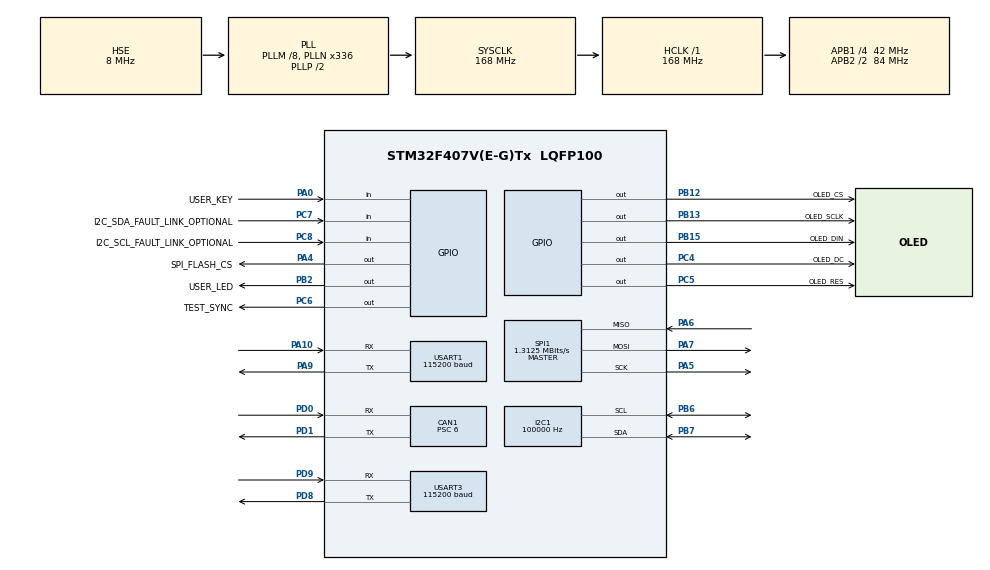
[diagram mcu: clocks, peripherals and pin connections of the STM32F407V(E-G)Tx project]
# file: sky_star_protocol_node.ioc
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CAN1.BS1=CAN_BS1_11TQ
CAN1.BS2=CAN_BS2_2TQ
CAN1.AutoBusOff=ENABLE
CAN1.AutoRetransmission=ENABLE
CAN1.CalculateBaudRate=500000
CAN1.CalculateTimeBit=2000
CAN1.CalculateTimeQuantum=142.85714285714286
CAN1.Prescaler=6
I2C1.ClockSpeed=100000
Mcu.Family=STM32F4
Mcu.Name=STM32F407V(E-G)Tx
Mcu.Package=LQFP100
PB12.GPIO_Label=OLED_CS
PB12.PinState=GPIO_PIN_SET
PB12.Signal=GPIO_Output
PB13.GPIO_Label=OLED_SCLK
PB13.Signal=GPIO_Output
PB15.GPIO_Label=OLED_DIN
PB15.Signal=GPIO_Output
PC4.GPIO_Label=OLED_DC
PC4.Signal=GPIO_Output
PC5.GPIO_Label=OLED_RES
PC5.PinState=GPIO_PIN_SET
PC5.Signal=GPIO_Output
PC7.GPIO_Label=I2C_SDA_FAULT_LINK_OPTIONAL
PC7.Signal=GPIO_Input
PC8.GPIO_Label=I2C_SCL_FAULT_LINK_OPTIONAL
PC8.Signal=GPIO_Input
NVIC.PriorityGroup=NVIC_PRIORITYGROUP_4
NVIC.USART1_IRQn=true\:5\:0\:false\:false\:true\:true\:true\:true
PA0-WKUP.GPIO_Label=USER_KEY
PA0-WKUP.GPIO_PuPd=GPIO_PULLDOWN
PA0-WKUP.Signal=GPIO_Input
PA10.Mode=Asynchronous
PA10.Signal=USART1_RX
PA13.Mode=Serial_Wire
PA13.Signal=SYS_JTMS-SWDIO
PA14.Mode=Serial_Wire
PA14.Signal=SYS_JTCK-SWCLK
PA4.GPIO_Label=SPI_FLASH_CS
PA4.GPIO_Speed=GPIO_SPEED_FREQ_HIGH
PA4.PinState=GPIO_PIN_SET
PA4.Signal=GPIO_Output
PA5.Mode=Full_Duplex_Master
PA5.Signal=SPI1_SCK
PA6.Mode=Full_Duplex_Master
PA6.Signal=SPI1_MISO
PA7.Mode=Full_Duplex_Master
PA7.Signal=SPI1_MOSI
PA9.Mode=Asynchronous
PA9.Signal=USART1_TX
PB2.GPIO_Label=USER_LED
PB2.GPIO_Speed=GPIO_SPEED_FREQ_LOW
PB2.PinState=GPIO_PIN_RESET
PB2.Signal=GPIO_Output
PB6.GPIO_Pu=GPIO_PULLUP
PB6.Mode=I2C
PB6.Signal=I2C1_SCL
PB7.GPIO_Pu=GPIO_PULLUP
PB7.Mode=I2C
PB7.Signal=I2C1_SDA
PC14-OSC32_IN.Mode=LSE-External-Oscillator
PC14-OSC32_IN.Signal=RCC_OSC32_IN
PC15-OSC32_OUT.Mode=LSE-External-Oscillator
PC15-OSC32_OUT.Signal=RCC_OSC32_OUT
PC6.GPIO_Label=TEST_SYNC
PC6.GPIO_Speed=GPIO_SPEED_FREQ_HIGH
PC6.PinState=GPIO_PIN_RESET
PC6.Signal=GPIO_Output
PD0.Mode=CAN_Activate
PD0.Signal=CAN1_RX
PD1.Mode=CAN_Activate
PD1.Signal=CAN1_TX
PD8.Mode=Asynchronous
PD8.Signal=USART3_TX
PD9.Mode=Asynchronous
PD9.Signal=USART3_RX
PH0-OSC_IN.Mode=HSE-External-Oscillator
PH0-OSC_IN.Signal=RCC_OSC_IN
PH1-OSC_OUT.Mode=HSE-External-Oscillator
PH1-OSC_OUT.Signal=RCC_OSC_OUT
ProjectManager.HeapSize=0x400
ProjectManager.StackSize=0x800
ProjectManager.TargetToolchain=MDK-ARM V5
RCC.48MHZClocksFreq_Value=48000000
RCC.AHBFreq_Value=168000000
RCC.APB1CLKDivider=RCC_HCLK_DIV4
RCC.APB1Freq_Value=42000000
RCC.APB1TimFreq_Value=84000000
RCC.APB2CLKDivider=RCC_HCLK_DIV2
RCC.APB2Freq_Value=84000000
RCC.APB2TimFreq_Value=168000000
RCC.CortexFreq_Value=168000000
RCC.HCLKFreq_Value=168000000
RCC.HSE_VALUE=8000000
RCC.HSI_VALUE=16000000
RCC.PLLM=8
RCC.PLLN=336
RCC.PLLQ=7
RCC.PLLSourceVirtual=RCC_PLLSOURCE_HSE
RCC.SYSCLKFreq_VALUE=168000000
RCC.SYSCLKSource=RCC_SYSCLKSOURCE_PLLCLK
RCC.VCOOutputFreq_Value=336000000
SPI1.BaudRatePrescaler=SPI_BAUDRATEPRESCALER_64
SPI1.CalculateBaudRate=1.3125 MBits/s
SPI1.Direction=SPI_DIRECTION_2LINES
SPI1.Mode=SPI_MODE_MASTER
SPI1.VirtualType=VM_MASTER
USART1.BaudRate=115200
USART1.VirtualMode=VM_ASYNC
USART3.BaudRate=115200
USART3.VirtualMode=VM_ASYNC
board=custom

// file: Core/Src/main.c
/* USER CODE BEGIN Header */
/**
  ******************************************************************************
  * @file           : main.c
  * @brief          : Main program body
  ******************************************************************************
  * @attention
  *
  * Copyright (c) 2026 STMicroelectronics.
  * All rights reserved.
  *
  * This software is licensed under terms that can be found in the LICENSE file
  * in the root directory of this software component.
  * If no LICENSE file comes with this software, it is provided AS-IS.
  *
  ******************************************************************************
  */
/* USER CODE END Header */
#include "main.h"

/* USER CODE BEGIN Includes */
#include "mc_board_app.h"
/* USER CODE END Includes */

CAN_HandleTypeDef hcan1;

I2C_HandleTypeDef hi2c1;

SPI_HandleTypeDef hspi1;

UART_HandleTypeDef huart1;
UART_HandleTypeDef huart3;

void SystemClock_Config(void);
static void MX_GPIO_Init(void);
static void MX_CAN1_Init(void);
static void MX_I2C1_Init(void);
static void MX_SPI1_Init(void);
static void MX_USART1_UART_Init(void);
static void MX_USART3_UART_Init(void);

int main(void)
{

  /* MCU Configuration--------------------------------------------------------*/

  /* Reset of all peripherals, Initializes the Flash interface and the Systick. */
  HAL_Init();

  /* Configure the system clock */
  SystemClock_Config();

  /* Initialize all configured peripherals */
  MX_GPIO_Init();
  MX_CAN1_Init();
  MX_I2C1_Init();
  MX_SPI1_Init();
  MX_USART1_UART_Init();
  MX_USART3_UART_Init();
  /* USER CODE BEGIN 2 */
  mc_board_app_init();
  /* USER CODE END 2 */

  /* Infinite loop */
  while (1)
  {

    /* USER CODE BEGIN 3 */
    mc_board_app_poll();
  }
  /* USER CODE END 3 */
}

void SystemClock_Config(void)
{
  RCC_OscInitTypeDef RCC_OscInitStruct = {0};
  RCC_ClkInitTypeDef RCC_ClkInitStruct = {0};

  /** Configure the main internal regulator output voltage
  */
  __HAL_RCC_PWR_CLK_ENABLE();
  __HAL_PWR_VOLTAGESCALING_CONFIG(PWR_REGULATOR_VOLTAGE_SCALE1);

  /** Initializes the RCC Oscillators according to the specified parameters
  * in the RCC_OscInitTypeDef structure.
  */
  RCC_OscInitStruct.OscillatorType = RCC_OSCILLATORTYPE_HSE;
  RCC_OscInitStruct.HSEState = RCC_HSE_ON;
  RCC_OscInitStruct.PLL.PLLState = RCC_PLL_ON;
  RCC_OscInitStruct.PLL.PLLSource = RCC_PLLSOURCE_HSE;
  RCC_OscInitStruct.PLL.PLLM = 8;
  RCC_OscInitStruct.PLL.PLLN = 336;
  RCC_OscInitStruct.PLL.PLLP = RCC_PLLP_DIV2;
  RCC_OscInitStruct.PLL.PLLQ = 7;
  if (HAL_RCC_OscConfig(&RCC_OscInitStruct) != HAL_OK)
  {
    Error_Handler();
  }

  /** Initializes the CPU, AHB and APB buses clocks
  */
  RCC_ClkInitStruct.ClockType = RCC_CLOCKTYPE_HCLK|RCC_CLOCKTYPE_SYSCLK
                              |RCC_CLOCKTYPE_PCLK1|RCC_CLOCKTYPE_PCLK2;
  RCC_ClkInitStruct.SYSCLKSource = RCC_SYSCLKSOURCE_PLLCLK;
  RCC_ClkInitStruct.AHBCLKDivider = RCC_SYSCLK_DIV1;
  RCC_ClkInitStruct.APB1CLKDivider = RCC_HCLK_DIV4;
  RCC_ClkInitStruct.APB2CLKDivider = RCC_HCLK_DIV2;

  if (HAL_RCC_ClockConfig(&RCC_ClkInitStruct, FLASH_LATENCY_5) != HAL_OK)
  {
    Error_Handler();
  }
}

static void MX_CAN1_Init(void)
{

  hcan1.Instance = CAN1;
  hcan1.Init.Prescaler = 6;
  hcan1.Init.Mode = CAN_MODE_NORMAL;
  hcan1.Init.SyncJumpWidth = CAN_SJW_1TQ;
  hcan1.Init.TimeSeg1 = CAN_BS1_11TQ;
  hcan1.Init.TimeSeg2 = CAN_BS2_2TQ;
  hcan1.Init.TimeTriggeredMode = DISABLE;
  hcan1.Init.AutoBusOff = ENABLE;
  hcan1.Init.AutoWakeUp = DISABLE;
  hcan1.Init.AutoRetransmission = ENABLE;
  hcan1.Init.ReceiveFifoLocked = DISABLE;
  hcan1.Init.TransmitFifoPriority = DISABLE;
  if (HAL_CAN_Init(&hcan1) != HAL_OK)
  {
    Error_Handler();
  }

}

static void MX_I2C1_Init(void)
{

  hi2c1.Instance = I2C1;
  hi2c1.Init.ClockSpeed = 100000;
  hi2c1.Init.DutyCycle = I2C_DUTYCYCLE_2;
  hi2c1.Init.OwnAddress1 = 0;
  hi2c1.Init.AddressingMode = I2C_ADDRESSINGMODE_7BIT;
  hi2c1.Init.DualAddressMode = I2C_DUALADDRESS_DISABLE;
  hi2c1.Init.OwnAddress2 = 0;
  hi2c1.Init.GeneralCallMode = I2C_GENERALCALL_DISABLE;
  hi2c1.Init.NoStretchMode = I2C_NOSTRETCH_DISABLE;
  if (HAL_I2C_Init(&hi2c1) != HAL_OK)
  {
    Error_Handler();
  }

}

static void MX_SPI1_Init(void)
{

  /* SPI1 parameter configuration*/
  hspi1.Instance = SPI1;
  hspi1.Init.Mode = SPI_MODE_MASTER;
  hspi1.Init.Direction = SPI_DIRECTION_2LINES;
  hspi1.Init.DataSize = SPI_DATASIZE_8BIT;
  hspi1.Init.CLKPolarity = SPI_POLARITY_LOW;
  hspi1.Init.CLKPhase = SPI_PHASE_1EDGE;
  hspi1.Init.NSS = SPI_NSS_SOFT;
  hspi1.Init.BaudRatePrescaler = SPI_BAUDRATEPRESCALER_64;
  hspi1.Init.FirstBit = SPI_FIRSTBIT_MSB;
  hspi1.Init.TIMode = SPI_TIMODE_DISABLE;
  hspi1.Init.CRCCalculation = SPI_CRCCALCULATION_DISABLE;
  hspi1.Init.CRCPolynomial = 10;
  if (HAL_SPI_Init(&hspi1) != HAL_OK)
  {
    Error_Handler();
  }

}

static void MX_USART1_UART_Init(void)
{

  huart1.Instance = USART1;
  huart1.Init.BaudRate = 115200;
  huart1.Init.WordLength = UART_WORDLENGTH_8B;
  huart1.Init.StopBits = UART_STOPBITS_1;
  huart1.Init.Parity = UART_PARITY_NONE;
  huart1.Init.Mode = UART_MODE_TX_RX;
  huart1.Init.HwFlowCtl = UART_HWCONTROL_NONE;
  huart1.Init.OverSampling = UART_OVERSAMPLING_16;
  if (HAL_UART_Init(&huart1) != HAL_OK)
  {
    Error_Handler();
  }

}

static void MX_USART3_UART_Init(void)
{

  huart3.Instance = USART3;
  huart3.Init.BaudRate = 115200;
  huart3.Init.WordLength = UART_WORDLENGTH_8B;
  huart3.Init.StopBits = UART_STOPBITS_1;
  huart3.Init.Parity = UART_PARITY_NONE;
  huart3.Init.Mode = UART_MODE_TX_RX;
  huart3.Init.HwFlowCtl = UART_HWCONTROL_NONE;
  huart3.Init.OverSampling = UART_OVERSAMPLING_16;
  if (HAL_UART_Init(&huart3) != HAL_OK)
  {
    Error_Handler();
  }

}

static void MX_GPIO_Init(void)
{
  GPIO_InitTypeDef GPIO_InitStruct = {0};

  /* GPIO Ports Clock Enable */
  __HAL_RCC_GPIOC_CLK_ENABLE();
  __HAL_RCC_GPIOH_CLK_ENABLE();
  __HAL_RCC_GPIOA_CLK_ENABLE();
  __HAL_RCC_GPIOB_CLK_ENABLE();
  __HAL_RCC_GPIOD_CLK_ENABLE();

  /*Configure GPIO pin Output Level */
  HAL_GPIO_WritePin(SPI_FLASH_CS_GPIO_Port, SPI_FLASH_CS_Pin, GPIO_PIN_SET);

  /*Configure GPIO pin Output Level */
  HAL_GPIO_WritePin(USER_LED_GPIO_Port, USER_LED_Pin, GPIO_PIN_RESET);

  /*Configure GPIO pin Output Level */
  HAL_GPIO_WritePin(TEST_SYNC_GPIO_Port, TEST_SYNC_Pin, GPIO_PIN_RESET);

  /*Configure GPIO pin : USER_KEY_Pin */
  GPIO_InitStruct.Pin = USER_KEY_Pin;
  GPIO_InitStruct.Mode = GPIO_MODE_INPUT;
  GPIO_InitStruct.Pull = GPIO_PULLDOWN;
  HAL_GPIO_Init(USER_KEY_GPIO_Port, &GPIO_InitStruct);

  /*Configure GPIO pin : SPI_FLASH_CS_Pin */
  GPIO_InitStruct.Pin = SPI_FLASH_CS_Pin;
  GPIO_InitStruct.Mode = GPIO_MODE_OUTPUT_PP;
  GPIO_InitStruct.Pull = GPIO_NOPULL;
  GPIO_InitStruct.Speed = GPIO_SPEED_FREQ_HIGH;
  HAL_GPIO_Init(SPI_FLASH_CS_GPIO_Port, &GPIO_InitStruct);

  /*Configure GPIO pin : USER_LED_Pin */
  GPIO_InitStruct.Pin = USER_LED_Pin;
  GPIO_InitStruct.Mode = GPIO_MODE_OUTPUT_PP;
  GPIO_InitStruct.Pull = GPIO_NOPULL;
  GPIO_InitStruct.Speed = GPIO_SPEED_FREQ_LOW;
  HAL_GPIO_Init(USER_LED_GPIO_Port, &GPIO_InitStruct);

  /*Configure GPIO pin : TEST_SYNC_Pin */
  GPIO_InitStruct.Pin = TEST_SYNC_Pin;
  GPIO_InitStruct.Mode = GPIO_MODE_OUTPUT_PP;
  GPIO_InitStruct.Pull = GPIO_NOPULL;
  GPIO_InitStruct.Speed = GPIO_SPEED_FREQ_HIGH;
  HAL_GPIO_Init(TEST_SYNC_GPIO_Port, &GPIO_InitStruct);

}

void Error_Handler(void)
{
  __disable_irq();
  while (1)
  {
  }
}
